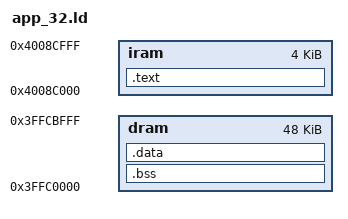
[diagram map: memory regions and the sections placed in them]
MEMORY {
  iram : org = 0x4008c000, len = 0x1000
  dram : org = 0x3ffc0000, len = 0xc000
}

ENTRY(ram_main)

SECTIONS {
  .text : ALIGN(4) {
    *(.literal)
    *(.text .text.*)
  } > iram

  .bss : ALIGN(4) {
     _bss_start = ABSOLUTE(.);
    *(.bss)
	_bss_end = ABSOLUTE(.);
  } > dram

  .data : ALIGN(4) {
    *(.data)
    *(.rodata .rodata.*)
  } > dram
}

INCLUDE "../../../../flasher_stub/ld/rom_32.ld"
